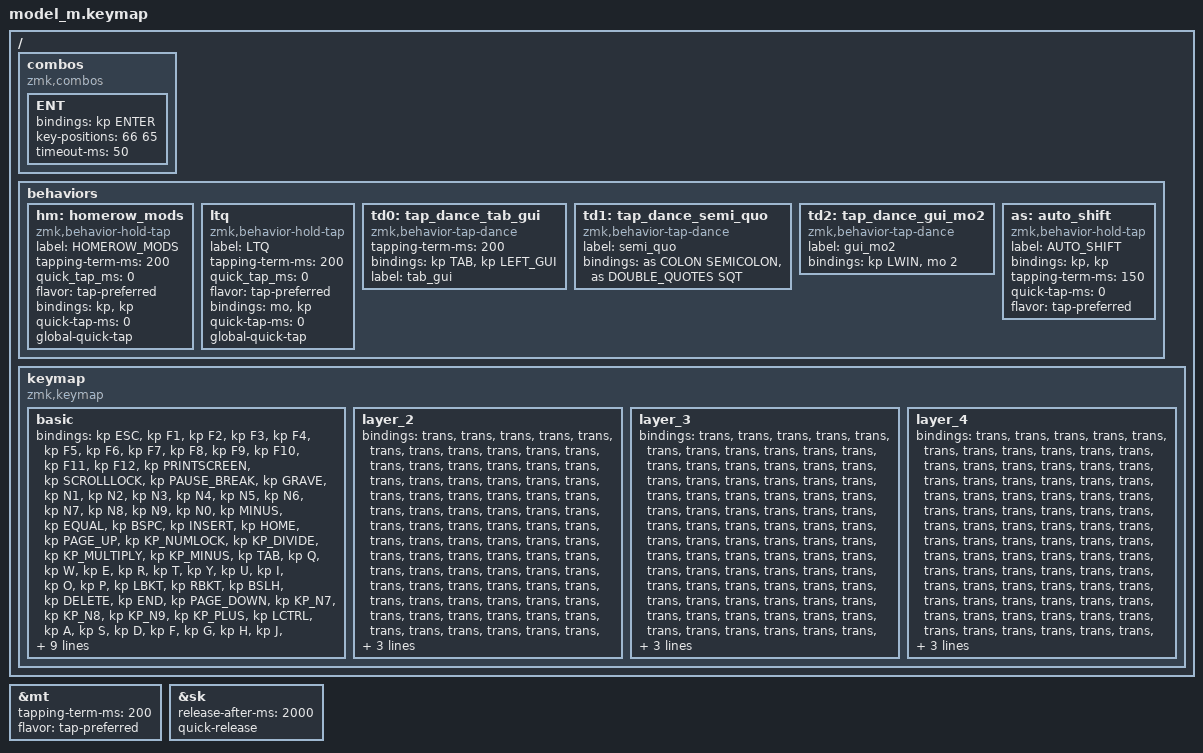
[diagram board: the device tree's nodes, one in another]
/*
 * Copyright (c) 2020 The ZMK Contributors
 *
 * SPDX-License-Identifier: MIT
 */

#include <behaviors.dtsi>
#include <dt-bindings/zmk/keys.h>

&mt {
    tapping-term-ms = <200>;
    flavor = "tap-preferred";
};

&sk {
    release-after-ms = <2000>;
    quick-release;
};

/ {
    combos {
        compatible = "zmk,combos";

        ENT {
            bindings = <&kp ENTER>;
            key-positions = <66 65>;
            timeout-ms = <50>;
        };
    };

    behaviors {
        hm: homerow_mods {
            compatible = "zmk,behavior-hold-tap";
            label = "HOMEROW_MODS";
            #binding-cells = <2>;
            tapping-term-ms = <200>;
            quick_tap_ms = <0>;
            flavor = "tap-preferred";
            bindings = <&kp>, <&kp>;

            quick-tap-ms = <0>;
            global-quick-tap;
        };

        ltq: ltq {
            compatible = "zmk,behavior-hold-tap";
            label = "LTQ";
            #binding-cells = <2>;
            tapping-term-ms = <200>;
            quick_tap_ms = <0>;
            flavor = "tap-preferred";
            bindings = <&mo>, <&kp>;

            quick-tap-ms = <0>;
            global-quick-tap;
        };

        td0: tap_dance_tab_gui {
            compatible = "zmk,behavior-tap-dance";
            #binding-cells = <0>;
            tapping-term-ms = <200>;
            bindings = <&kp TAB>, <&kp LEFT_GUI>;

            label = "tab_gui";
        };

        td1: tap_dance_semi_quo {
            compatible = "zmk,behavior-tap-dance";
            label = "semi_quo";
            #binding-cells = <0>;
            bindings = <&as COLON SEMICOLON>, <&as DOUBLE_QUOTES SQT>;
        };

        td2: tap_dance_gui_mo2 {
            compatible = "zmk,behavior-tap-dance";
            label = "gui_mo2";
            #binding-cells = <0>;
            bindings = <&kp LWIN>, <&mo 2>;
        };

        as: auto_shift {
            compatible = "zmk,behavior-hold-tap";
            label = "AUTO_SHIFT";
            bindings = <&kp>, <&kp>;

            #binding-cells = <2>;
            tapping-term-ms = <150>;
            quick-tap-ms = <0>;
            flavor = "tap-preferred";
        };
    };

    keymap {
        compatible = "zmk,keymap";

        basic {
            bindings = <
&kp ESC  &kp F1  &kp F2  &kp F3  &kp F4  &kp F5  &kp F6  &kp F7  &kp F8  &kp F9  &kp F10  &kp F11  &kp F12  &kp PRINTSCREEN  &kp SCROLLLOCK  &kp PAUSE_BREAK  &kp GRAVE  &kp N1  &kp N2  &kp N3  &kp N4  &kp N5  &kp N6  &kp N7  &kp N8  &kp N9  &kp N0  &kp MINUS  &kp EQUAL  &kp BSPC  &kp INSERT  &kp HOME  &kp PAGE_UP  &kp KP_NUMLOCK  &kp KP_DIVIDE  &kp KP_MULTIPLY  &kp KP_MINUS  &kp TAB  &kp Q  &kp W  &kp E  &kp R  &kp T  &kp Y  &kp U  &kp I  &kp O  &kp P  &kp LBKT  &kp RBKT  &kp BSLH  &kp DELETE  &kp END  &kp PAGE_DOWN  &kp KP_N7  &kp KP_N8  &kp KP_N9  &kp KP_PLUS  &kp LCTRL  &kp A  &kp S  &kp D  &kp F  &kp G  &kp H  &kp J  &kp K  &kp L  &kp SEMI  &kp APOS  &kp ENTER  &kp KP_N4  &kp KP_N5  &kp KP_N6  &kp LSHFT  &kp Z  &kp X  &kp C  &kp V  &kp B  &kp N  &kp M  &kp COMMA  &kp DOT  &kp FSLH  &kp RSHFT  &kp UP_ARROW  &kp KP_N1  &kp KP_N2  &kp KP_N3  &kp KP_ENTER  &kp LGUI  &kp LALT  &kp SPACE  &kp CAPS  &kp RGUI  &kp LEFT_ARROW  &kp DOWN_ARROW  &kp RIGHT_ARROW  &kp KP_N0  &kp KP_DOT
            >;
        };

        layer_2 {
            bindings = <
&trans  &trans  &trans  &trans  &trans  &trans  &trans  &trans  &trans  &trans  &trans  &trans  &trans  &trans  &trans  &trans  &trans  &trans  &trans  &trans  &trans  &trans  &trans  &trans  &trans  &trans  &trans  &trans  &trans  &trans  &trans  &trans  &trans  &trans  &trans  &trans  &trans  &trans  &trans  &trans  &trans  &trans  &trans  &trans  &trans  &trans  &trans  &trans  &trans  &trans  &trans  &trans  &trans  &trans  &trans  &trans  &trans  &trans  &trans  &trans  &trans  &trans  &trans  &trans  &trans  &trans  &trans  &trans  &trans  &trans  &trans  &trans  &trans  &trans  &trans  &trans  &trans  &trans  &trans  &trans  &trans  &trans  &trans  &trans  &trans  &trans  &trans  &trans  &trans  &trans  &trans  &trans  &trans  &trans  &trans  &trans  &trans  &trans  &trans  &trans  &trans
            >;
        };

        layer_3 {
            bindings = <
&trans  &trans  &trans  &trans  &trans  &trans  &trans  &trans  &trans  &trans  &trans  &trans  &trans  &trans  &trans  &trans  &trans  &trans  &trans  &trans  &trans  &trans  &trans  &trans  &trans  &trans  &trans  &trans  &trans  &trans  &trans  &trans  &trans  &trans  &trans  &trans  &trans  &trans  &trans  &trans  &trans  &trans  &trans  &trans  &trans  &trans  &trans  &trans  &trans  &trans  &trans  &trans  &trans  &trans  &trans  &trans  &trans  &trans  &trans  &trans  &trans  &trans  &trans  &trans  &trans  &trans  &trans  &trans  &trans  &trans  &trans  &trans  &trans  &trans  &trans  &trans  &trans  &trans  &trans  &trans  &trans  &trans  &trans  &trans  &trans  &trans  &trans  &trans  &trans  &trans  &trans  &trans  &trans  &trans  &trans  &trans  &trans  &trans  &trans  &trans  &trans
            >;
        };

        layer_4 {
            bindings = <
&trans  &trans  &trans  &trans  &trans  &trans  &trans  &trans  &trans  &trans  &trans  &trans  &trans  &trans  &trans  &trans  &trans  &trans  &trans  &trans  &trans  &trans  &trans  &trans  &trans  &trans  &trans  &trans  &trans  &trans  &trans  &trans  &trans  &trans  &trans  &trans  &trans  &trans  &trans  &trans  &trans  &trans  &trans  &trans  &trans  &trans  &trans  &trans  &trans  &trans  &trans  &trans  &trans  &trans  &trans  &trans  &trans  &trans  &trans  &trans  &trans  &trans  &trans  &trans  &trans  &trans  &trans  &trans  &trans  &trans  &trans  &trans  &trans  &trans  &trans  &trans  &trans  &trans  &trans  &trans  &trans  &trans  &trans  &trans  &trans  &trans  &trans  &trans  &trans  &trans  &trans  &trans  &trans  &trans  &trans  &trans  &trans  &trans  &trans  &trans  &trans
            >;
        };
    };
};
